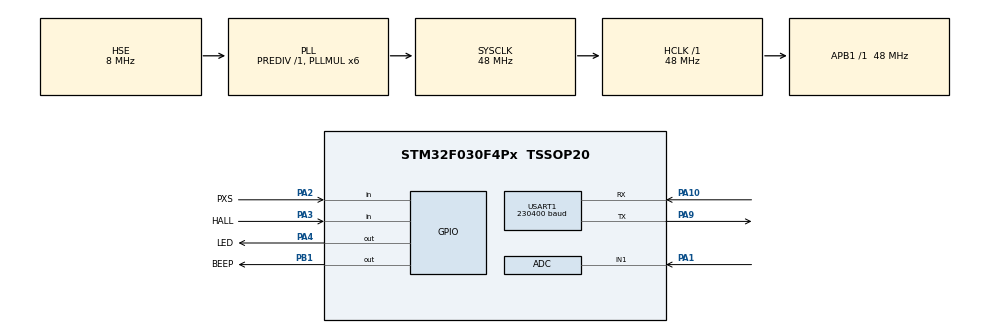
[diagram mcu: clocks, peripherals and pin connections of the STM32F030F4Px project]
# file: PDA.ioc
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ADC.ClockPrescaler=ADC_CLOCK_ASYNC_DIV1
ADC.ContinuousConvMode=ENABLE
Dma.ADC.2.Direction=DMA_PERIPH_TO_MEMORY
Dma.ADC.2.Instance=DMA1_Channel1
Dma.ADC.2.MemDataAlignment=DMA_MDATAALIGN_HALFWORD
Dma.ADC.2.MemInc=DMA_MINC_ENABLE
Dma.ADC.2.Mode=DMA_NORMAL
Dma.ADC.2.PeriphDataAlignment=DMA_PDATAALIGN_HALFWORD
Dma.ADC.2.PeriphInc=DMA_PINC_DISABLE
Dma.ADC.2.Priority=DMA_PRIORITY_VERY_HIGH
Dma.Request0=USART1_RX
Dma.Request1=USART1_TX
Dma.Request2=ADC
Dma.USART1_RX.0.Direction=DMA_PERIPH_TO_MEMORY
Dma.USART1_RX.0.Instance=DMA1_Channel3
Dma.USART1_RX.0.MemDataAlignment=DMA_MDATAALIGN_BYTE
Dma.USART1_RX.0.MemInc=DMA_MINC_ENABLE
Dma.USART1_RX.0.Mode=DMA_NORMAL
Dma.USART1_RX.0.PeriphDataAlignment=DMA_PDATAALIGN_BYTE
Dma.USART1_RX.0.PeriphInc=DMA_PINC_DISABLE
Dma.USART1_RX.0.Priority=DMA_PRIORITY_MEDIUM
Dma.USART1_TX.1.Direction=DMA_MEMORY_TO_PERIPH
Dma.USART1_TX.1.Instance=DMA1_Channel2
Dma.USART1_TX.1.MemDataAlignment=DMA_MDATAALIGN_BYTE
Dma.USART1_TX.1.MemInc=DMA_MINC_ENABLE
Dma.USART1_TX.1.Mode=DMA_NORMAL
Dma.USART1_TX.1.PeriphDataAlignment=DMA_PDATAALIGN_BYTE
Dma.USART1_TX.1.PeriphInc=DMA_PINC_DISABLE
Dma.USART1_TX.1.Priority=DMA_PRIORITY_MEDIUM
Mcu.Family=STM32F0
Mcu.Name=STM32F030F4Px
Mcu.Package=TSSOP20
NVIC.ADC1_IRQn=true\:0\:0\:false\:false\:true\:true\:true\:true
NVIC.DMA1_Channel1_IRQn=true\:0\:0\:false\:false\:true\:false\:true\:true
NVIC.DMA1_Channel2_3_IRQn=true\:0\:0\:false\:false\:true\:false\:true\:true
NVIC.TIM1_BRK_UP_TRG_COM_IRQn=true\:0\:0\:false\:false\:true\:true\:true\:true
NVIC.USART1_IRQn=true\:0\:0\:false\:false\:true\:true\:true\:true
PA1.Mode=IN1
PA1.Signal=ADC_IN1
PA10.Mode=Asynchronous
PA10.Signal=USART1_RX
PA13.Mode=Serial_Wire
PA13.Signal=SYS_SWDIO
PA14.Mode=Serial_Wire
PA14.Signal=SYS_SWCLK
PA2.GPIO_Label=PXS
PA2.Signal=GPIO_Input
PA3.GPIO_Label=HALL
PA3.Signal=GPIO_Input
PA4.GPIO_Label=LED
PA4.GPIO_ModeDefaultOutputPP=GPIO_MODE_OUTPUT_PP
PA4.GPIO_PuPd=GPIO_NOPULL
PA4.Signal=GPIO_Output
PA9.Mode=Asynchronous
PA9.Signal=USART1_TX
PB1.GPIO_Label=BEEP
PB1.Signal=GPIO_Output
PF0-OSC_IN.Mode=HSE-External-Oscillator
PF0-OSC_IN.Signal=RCC_OSC_IN
PF1-OSC_OUT.Mode=HSE-External-Oscillator
PF1-OSC_OUT.Signal=RCC_OSC_OUT
ProjectManager.HeapSize=0x200
ProjectManager.StackSize=0x400
ProjectManager.TargetToolchain=MDK-ARM V5.27
RCC.AHBFreq_Value=48000000
RCC.APB1Freq_Value=48000000
RCC.APB1TimFreq_Value=48000000
RCC.HCLKFreq_Value=48000000
RCC.PLLMUL=RCC_PLL_MUL6
RCC.PLLSourceVirtual=RCC_PLLSOURCE_HSE
RCC.SYSCLKFreq_VALUE=48000000
RCC.SYSCLKSource=RCC_SYSCLKSOURCE_PLLCLK
RCC.Usart1ClockSelection=RCC_USART1CLKSOURCE_SYSCLK
TIM1.AutoReloadPreload=TIM_AUTORELOAD_PRELOAD_ENABLE
TIM1.Period=9
TIM1.Prescaler=479
USART1.BaudRate=230400
USART1.VirtualMode-Asynchronous=VM_ASYNC
VP_TIM1_VS_ClockSourceINT.Mode=Internal
board=custom

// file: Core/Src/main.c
/* USER CODE BEGIN Header */
/**
  ******************************************************************************
  * @file           : main.c
  * @brief          : Main program body
  ******************************************************************************
  * @attention
  *
  * Copyright (c) 2026 STMicroelectronics.
  * All rights reserved.
  *
  * This software is licensed under terms that can be found in the LICENSE file
  * in the root directory of this software component.
  * If no LICENSE file comes with this software, it is provided AS-IS.
  *
  ******************************************************************************
  */
/* USER CODE END Header */
#include "main.h"
#include "adc.h"
#include "dma.h"
#include "tim.h"
#include "usart.h"
#include "gpio.h"

/* USER CODE BEGIN PD */
GPIO_PinState HALL_state;
GPIO_PinState PXS_state;
/* USER CODE END PD */

void SystemClock_Config(void);

int main(void)
{

  /* MCU Configuration--------------------------------------------------------*/

  /* Reset of all peripherals, Initializes the Flash interface and the Systick. */
  HAL_Init();

  /* Configure the system clock */
  SystemClock_Config();

  /* Initialize all configured peripherals */
  MX_GPIO_Init();
  MX_DMA_Init();
  MX_ADC_Init();
  MX_USART1_UART_Init();
  MX_TIM1_Init();
  /* USER CODE BEGIN 2 */
  HAL_ADCEx_Calibration_Start(&hadc);
  HAL_TIM_Base_Start_IT(&htim1);
  /* USER CODE END 2 */

  /* Infinite loop */
  /* USER CODE BEGIN WHILE */
  while (1)
  {

//    HALL_state = HAL_GPIO_ReadPin(HALL_GPIO_Port, HALL_Pin);
//    PXS_state = HAL_GPIO_ReadPin(PXS_GPIO_Port, PXS_Pin);
//    HAL_Delay(1000);
    /* USER CODE END WHILE */

  }
}

void SystemClock_Config(void)
{
  RCC_OscInitTypeDef RCC_OscInitStruct = {0};
  RCC_ClkInitTypeDef RCC_ClkInitStruct = {0};
  RCC_PeriphCLKInitTypeDef PeriphClkInit = {0};

  /** Initializes the RCC Oscillators according to the specified parameters
  * in the RCC_OscInitTypeDef structure.
  */
  RCC_OscInitStruct.OscillatorType = RCC_OSCILLATORTYPE_HSI14|RCC_OSCILLATORTYPE_HSE;
  RCC_OscInitStruct.HSEState = RCC_HSE_ON;
  RCC_OscInitStruct.HSI14State = RCC_HSI14_ON;
  RCC_OscInitStruct.HSI14CalibrationValue = 16;
  RCC_OscInitStruct.PLL.PLLState = RCC_PLL_ON;
  RCC_OscInitStruct.PLL.PLLSource = RCC_PLLSOURCE_HSE;
  RCC_OscInitStruct.PLL.PLLMUL = RCC_PLL_MUL6;
  RCC_OscInitStruct.PLL.PREDIV = RCC_PREDIV_DIV1;
  if (HAL_RCC_OscConfig(&RCC_OscInitStruct) != HAL_OK)
  {
    Error_Handler();
  }

  /** Initializes the CPU, AHB and APB buses clocks
  */
  RCC_ClkInitStruct.ClockType = RCC_CLOCKTYPE_HCLK|RCC_CLOCKTYPE_SYSCLK
                              |RCC_CLOCKTYPE_PCLK1;
  RCC_ClkInitStruct.SYSCLKSource = RCC_SYSCLKSOURCE_PLLCLK;
  RCC_ClkInitStruct.AHBCLKDivider = RCC_SYSCLK_DIV1;
  RCC_ClkInitStruct.APB1CLKDivider = RCC_HCLK_DIV1;

  if (HAL_RCC_ClockConfig(&RCC_ClkInitStruct, FLASH_LATENCY_1) != HAL_OK)
  {
    Error_Handler();
  }
  PeriphClkInit.PeriphClockSelection = RCC_PERIPHCLK_USART1;
  PeriphClkInit.Usart1ClockSelection = RCC_USART1CLKSOURCE_SYSCLK;
  if (HAL_RCCEx_PeriphCLKConfig(&PeriphClkInit) != HAL_OK)
  {
    Error_Handler();
  }
}

void Error_Handler(void)
{
  __disable_irq();
  while (1)
  {
  }
}
